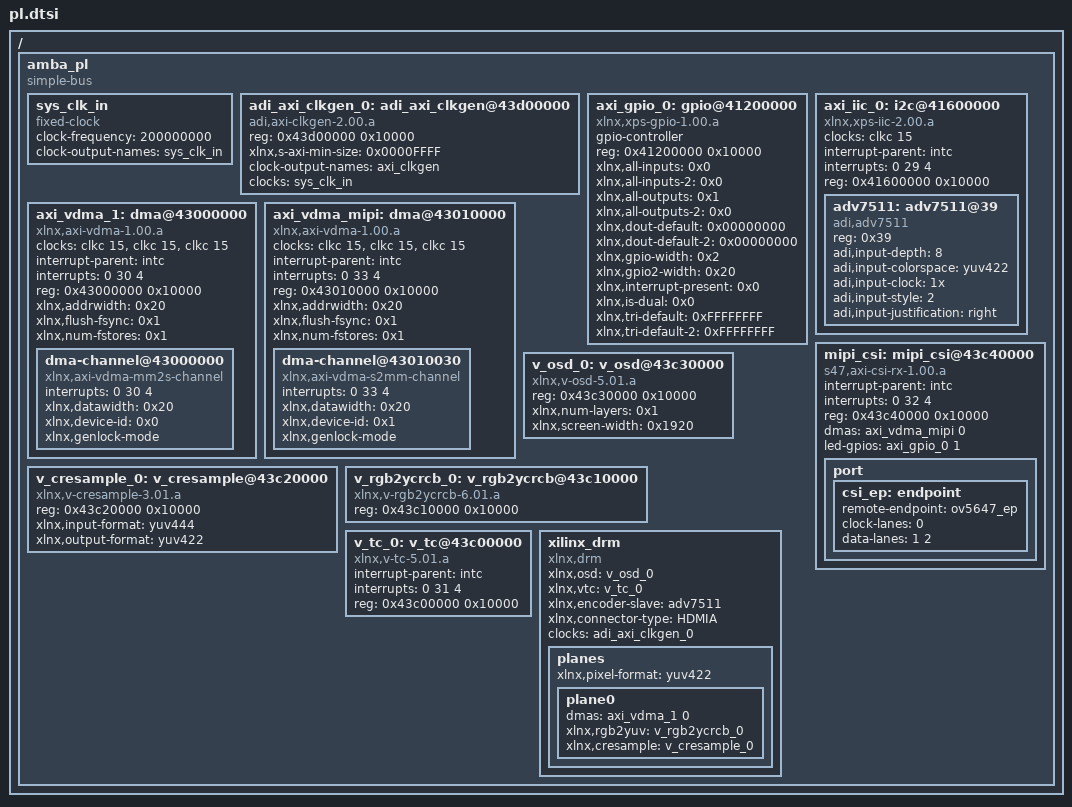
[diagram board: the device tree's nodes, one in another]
/*
 * CAUTION: This file is automatically generated by Xilinx.
 * Version:  
 * Today is: Wed Oct 25 10:43:29 2017
*/


/ {
	amba_pl: amba_pl {
		#address-cells = <1>;
		#size-cells = <1>;
		compatible = "simple-bus";
		ranges ;
		sys_clk_in: sys_clk_in {
			compatible = "fixed-clock";
			#clock-cells = <0>;
			clock-frequency = <200000000>;
			clock-output-names = "sys_clk_in";
		};
		adi_axi_clkgen_0: adi_axi_clkgen@43d00000 {
			compatible = "adi,axi-clkgen-2.00.a";
			reg = <0x43d00000 0x10000>;
			#clock-cells = <0>;
			xlnx,s-axi-min-size = <0x0000FFFF>;
			clock-output-names = "axi_clkgen";
			clocks = <&sys_clk_in>;
		};
		axi_gpio_0: gpio@41200000 {
			#gpio-cells = <2>;
			compatible = "xlnx,xps-gpio-1.00.a";
			gpio-controller ;
			reg = <0x41200000 0x10000>;
			xlnx,all-inputs = <0x0>;
			xlnx,all-inputs-2 = <0x0>;
			xlnx,all-outputs = <0x1>;
			xlnx,all-outputs-2 = <0x0>;
			xlnx,dout-default = <0x00000000>;
			xlnx,dout-default-2 = <0x00000000>;
			xlnx,gpio-width = <0x2>;
			xlnx,gpio2-width = <0x20>;
			xlnx,interrupt-present = <0x0>;
			xlnx,is-dual = <0x0>;
			xlnx,tri-default = <0xFFFFFFFF>;
			xlnx,tri-default-2 = <0xFFFFFFFF>;
		};
		axi_iic_0: i2c@41600000 {
			#address-cells = <1>;
			#size-cells = <0>;
			clock-names = "ref_clk";
			clocks = <&clkc 15>;
			compatible = "xlnx,xps-iic-2.00.a";
			interrupt-parent = <&intc>;
			interrupts = <0 29 4>;
			reg = <0x41600000 0x10000>;
			
			adv7511: adv7511@39 {
				compatible = "adi,adv7511";
				reg = <0x39>;
				adi,input-depth = <8>;
				adi,input-colorspace = "yuv422";
				adi,input-clock = "1x";
				adi,input-style = <2>;
				adi,input-justification = "right";
			};
		};
		axi_vdma_1: dma@43000000 {
			#dma-cells = <1>;
			clock-names = "s_axi_lite_aclk", "m_axi_mm2s_aclk", "m_axi_mm2s_aclk";
			clocks = <&clkc 15>, <&clkc 15>, <&clkc 15>;
			compatible = "xlnx,axi-vdma-1.00.a";
			interrupt-parent = <&intc>;
			interrupts = <0 30 4>;
			reg = <0x43000000 0x10000>;
			xlnx,addrwidth = <0x20>;
			xlnx,flush-fsync = <0x1>;
			xlnx,num-fstores = <0x1>;
			dma-channel@43000000 {
				compatible = "xlnx,axi-vdma-mm2s-channel";
				interrupts = <0 30 4>;
				xlnx,datawidth = <0x20>;
				xlnx,device-id = <0x0>;
				xlnx,genlock-mode ;
			};
		};
		axi_vdma_mipi: dma@43010000 {
			#dma-cells = <1>;
			clock-names = "s_axi_lite_aclk", "m_axi_s2mm_aclk", "m_axi_s2mm_aclk";
			clocks = <&clkc 15>, <&clkc 15>, <&clkc 15>;
			compatible = "xlnx,axi-vdma-1.00.a";
			interrupt-parent = <&intc>;
			interrupts = <0 33 4>;
			reg = <0x43010000 0x10000>;
			xlnx,addrwidth = <0x20>;
			xlnx,flush-fsync = <0x1>;
			xlnx,num-fstores = <0x1>;
			dma-channel@43010030 {
				compatible = "xlnx,axi-vdma-s2mm-channel";
				interrupts = <0 33 4>;
				xlnx,datawidth = <0x20>;
				xlnx,device-id = <0x1>;
				xlnx,genlock-mode ;
			};
		};
		mipi_csi: mipi_csi@43c40000 {
			compatible = "s47,axi-csi-rx-1.00.a";
			interrupt-parent = <&intc>;
			interrupts = <0 32 4>;
			reg = <0x43c40000 0x10000>;

			dmas = <&axi_vdma_mipi 0>;
			dma-names = "video";

			led-gpios = <&axi_gpio_0 1 0>;

			port {
				csi_ep: endpoint {
					remote-endpoint = <&ov5647_ep>;
					clock-lanes = <0>;
					data-lanes = <1 2>;
				};
			};
		};
		v_cresample_0: v_cresample@43c20000 {
			compatible = "xlnx,v-cresample-3.01.a";
			reg = <0x43c20000 0x10000>;
			xlnx,input-format = "yuv444";
			xlnx,output-format = "yuv422";
		};
		v_osd_0: v_osd@43c30000 {
			compatible = "xlnx,v-osd-5.01.a";
			reg = <0x43c30000 0x10000>;
			xlnx,num-layers = <0x1>;
			xlnx,screen-width = <0x1920>;
		};
		v_rgb2ycrcb_0: v_rgb2ycrcb@43c10000 {
			compatible = "xlnx,v-rgb2ycrcb-6.01.a";
			reg = <0x43c10000 0x10000>;
		};
		v_tc_0: v_tc@43c00000 {
			compatible = "xlnx,v-tc-5.01.a";
			interrupt-parent = <&intc>;
			interrupts = <0 31 4>;
			reg = <0x43c00000 0x10000>;
		};
		xilinx_drm {
			compatible = "xlnx,drm";
			xlnx,osd = <&v_osd_0>;
			xlnx,vtc = <&v_tc_0>;
			xlnx,encoder-slave = <&adv7511>;
			xlnx,connector-type = "HDMIA";
			clocks = <&adi_axi_clkgen_0>;
			planes {
				xlnx,pixel-format = "yuv422";
				plane0 {
					dmas = <&axi_vdma_1 0>;
					dma-names = "dma";
					xlnx,rgb2yuv = <&v_rgb2ycrcb_0>;
					xlnx,cresample = <&v_cresample_0>;
				};
			};
		};
	};
};
